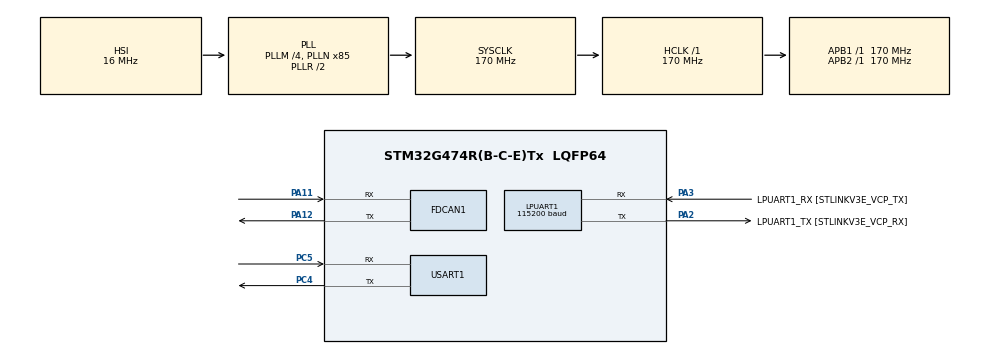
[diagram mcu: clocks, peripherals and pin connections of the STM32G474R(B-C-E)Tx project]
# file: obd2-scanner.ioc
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FDCAN1.CalculateBaudRateNominal=500000
FDCAN1.CalculateTimeBitNominal=2000
FDCAN1.CalculateTimeQuantumNominal=100.0
FDCAN1.NominalPrescaler=17
FDCAN1.NominalTimeSeg1=15
FDCAN1.NominalTimeSeg2=4
FDCAN1.StdFiltersNbr=1
FREERTOS.Tasks01=defaultTask,24,128,StartDefaultTask,Default,NULL,Dynamic,NULL,NULL
LPUART1.BaudRate=115200
Mcu.Family=STM32G4
Mcu.Name=STM32G474R(B-C-E)Tx
Mcu.Package=LQFP64
NVIC.FDCAN1_IT0_IRQn=true\:5\:0\:false\:false\:true\:true\:true\:true\:true
NVIC.PriorityGroup=NVIC_PRIORITYGROUP_4
NVIC.TIM6_DAC_IRQn=true\:15\:0\:false\:false\:true\:false\:false\:true\:true
NVIC.TimeBase=TIM6_DAC_IRQn
NVIC.TimeBaseIP=TIM6
PA11.Mode=FDCAN_Activate
PA11.Signal=FDCAN1_RX
PA12.Mode=FDCAN_Activate
PA12.Signal=FDCAN1_TX
PA13.GPIO_Label=T_SWDIO
PA13.Mode=Serial_Wire
PA13.Signal=SYS_JTMS-SWDIO
PA14.GPIO_Label=T_SWCLK
PA14.Mode=Serial_Wire
PA14.Signal=SYS_JTCK-SWCLK
PA2.GPIO_Label=LPUART1_TX [STLINKV3E_VCP_RX]
PA2.Mode=Asynchronous
PA2.Signal=LPUART1_TX
PA3.GPIO_Label=LPUART1_RX [STLINKV3E_VCP_TX]
PA3.Mode=Asynchronous
PA3.Signal=LPUART1_RX
PB3.GPIO_Label=T_SWO
PB3.Signal=SYS_JTDO-SWO
PC14-OSC32_IN.GPIO_Label=RCC_OSC32_IN
PC14-OSC32_IN.Mode=LSE-External-Oscillator
PC14-OSC32_IN.Signal=RCC_OSC32_IN
PC15-OSC32_OUT.GPIO_Label=RCC_OSC32_OUT
PC15-OSC32_OUT.Mode=LSE-External-Oscillator
PC15-OSC32_OUT.Signal=RCC_OSC32_OUT
PC4.Mode=Asynchronous
PC4.Signal=USART1_TX
PC5.Mode=Asynchronous
PC5.Signal=USART1_RX
PF0-OSC_IN.GPIO_Label=RCC_OSC_IN
PF0-OSC_IN.Mode=HSE-External-Clock-Source
PF0-OSC_IN.Signal=RCC_OSC_IN
PF1-OSC_OUT.GPIO_Label=RCC_OSC_OUT
PF1-OSC_OUT.Signal=RCC_OSC_OUT
ProjectManager.HeapSize=0x200
ProjectManager.StackSize=0x400
ProjectManager.TargetToolchain=CMake
RCC.ADC12Freq_Value=170000000
RCC.ADC345Freq_Value=170000000
RCC.AHBFreq_Value=170000000
RCC.APB1Freq_Value=170000000
RCC.APB1TimFreq_Value=170000000
RCC.APB2Freq_Value=170000000
RCC.APB2TimFreq_Value=170000000
RCC.CortexFreq_Value=170000000
RCC.EXTERNAL_CLOCK_VALUE=12288000
RCC.HCLKFreq_Value=170000000
RCC.HSE_VALUE=24000000
RCC.HSI48_VALUE=48000000
RCC.HSI_VALUE=16000000
RCC.PLLM=RCC_PLLM_DIV4
RCC.PLLN=85
RCC.RTCClockSelection=RCC_RTCCLKSOURCE_LSE
RCC.SYSCLKFreq_VALUE=170000000
RCC.SYSCLKSource=RCC_SYSCLKSOURCE_PLLCLK
RCC.USBFreq_Value=170000000
RCC.VCOOutputFreq_Value=340000000
USART1.VirtualMode-Asynchronous=VM_ASYNC
VP_FREERTOS_VS_CMSIS_V2.Mode=CMSIS_V2
VP_SYS_VS_DBSignals.Mode=DisableDeadBatterySignals
VP_SYS_VS_tim6.Mode=TIM6
board=NUCLEO-G474RE

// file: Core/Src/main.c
/* USER CODE BEGIN Header */
/**
  ******************************************************************************
  * @file           : main.c
  * @brief          : Main program body
  ******************************************************************************
  * @attention
  *
  * Copyright (c) 2026 STMicroelectronics.
  * All rights reserved.
  *
  * This software is licensed under terms that can be found in the LICENSE file
  * in the root directory of this software component.
  * If no LICENSE file comes with this software, it is provided AS-IS.
  *
  ******************************************************************************
  */
/* USER CODE END Header */
#include "main.h"
#include "cmsis_os.h"
#include "fdcan.h"
#include "usart.h"
#include "gpio.h"
#include <stdio.h>

void SystemClock_Config(void);
void MX_FREERTOS_Init(void);

/* USER CODE BEGIN 0 */
int _write(int file, char *ptr, int len)
{
  HAL_UART_Transmit(&hlpuart1, (uint8_t*) ptr, len, HAL_MAX_DELAY);
  return len;
}
/* USER CODE END 0 */

int main(void)
{

  /* MCU Configuration--------------------------------------------------------*/

  /* Reset of all peripherals, Initializes the Flash interface and the Systick. */
  HAL_Init();

  /* Configure the system clock */
  SystemClock_Config();

  /* Initialize all configured peripherals */
  MX_GPIO_Init();
  MX_FDCAN1_Init();
  MX_LPUART1_UART_Init();
  MX_USART1_UART_Init();
  /* USER CODE BEGIN 2 */

  // size_t free_heap = xPortGetFreeHeapSize(); // DEBUG
  // printf("free heap : %u", free_heap);

  /* USER CODE END 2 */

  /* Init scheduler */
  osKernelInitialize();  /* Call init function for freertos objects (in cmsis_os2.c) */
  MX_FREERTOS_Init();

  /* Start scheduler */
  osKernelStart();

  /* We should never get here as control is now taken by the scheduler */

  /* Infinite loop */
  while (1)
  {

  }
}

void SystemClock_Config(void)
{
  RCC_OscInitTypeDef RCC_OscInitStruct = {0};
  RCC_ClkInitTypeDef RCC_ClkInitStruct = {0};

  /** Configure the main internal regulator output voltage
  */
  HAL_PWREx_ControlVoltageScaling(PWR_REGULATOR_VOLTAGE_SCALE1_BOOST);

  /** Initializes the RCC Oscillators according to the specified parameters
  * in the RCC_OscInitTypeDef structure.
  */
  RCC_OscInitStruct.OscillatorType = RCC_OSCILLATORTYPE_HSI;
  RCC_OscInitStruct.HSIState = RCC_HSI_ON;
  RCC_OscInitStruct.HSICalibrationValue = RCC_HSICALIBRATION_DEFAULT;
  RCC_OscInitStruct.PLL.PLLState = RCC_PLL_ON;
  RCC_OscInitStruct.PLL.PLLSource = RCC_PLLSOURCE_HSI;
  RCC_OscInitStruct.PLL.PLLM = RCC_PLLM_DIV4;
  RCC_OscInitStruct.PLL.PLLN = 85;
  RCC_OscInitStruct.PLL.PLLP = RCC_PLLP_DIV2;
  RCC_OscInitStruct.PLL.PLLQ = RCC_PLLQ_DIV2;
  RCC_OscInitStruct.PLL.PLLR = RCC_PLLR_DIV2;
  if (HAL_RCC_OscConfig(&RCC_OscInitStruct) != HAL_OK)
  {
    Error_Handler();
  }

  /** Initializes the CPU, AHB and APB buses clocks
  */
  RCC_ClkInitStruct.ClockType = RCC_CLOCKTYPE_HCLK|RCC_CLOCKTYPE_SYSCLK
                              |RCC_CLOCKTYPE_PCLK1|RCC_CLOCKTYPE_PCLK2;
  RCC_ClkInitStruct.SYSCLKSource = RCC_SYSCLKSOURCE_PLLCLK;
  RCC_ClkInitStruct.AHBCLKDivider = RCC_SYSCLK_DIV1;
  RCC_ClkInitStruct.APB1CLKDivider = RCC_HCLK_DIV1;
  RCC_ClkInitStruct.APB2CLKDivider = RCC_HCLK_DIV1;

  if (HAL_RCC_ClockConfig(&RCC_ClkInitStruct, FLASH_LATENCY_4) != HAL_OK)
  {
    Error_Handler();
  }
}

void HAL_TIM_PeriodElapsedCallback(TIM_HandleTypeDef *htim)
{
  if (htim->Instance == TIM6)
  {
    HAL_IncTick();
  }
}

void Error_Handler(void)
{
  __disable_irq();
  while (1)
  {
  }
}

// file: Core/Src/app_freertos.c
/* USER CODE BEGIN Header */
/**
  ******************************************************************************
  * File Name          : app_freertos.c
  * Description        : Code for freertos applications
  ******************************************************************************
  * @attention
  *
  * Copyright (c) 2026 STMicroelectronics.
  * All rights reserved.
  *
  * This software is licensed under terms that can be found in the LICENSE file
  * in the root directory of this software component.
  * If no LICENSE file comes with this software, it is provided AS-IS.
  *
  ******************************************************************************
  */
/* USER CODE END Header */

#include "FreeRTOS.h"
#include "cmsis_os2.h"
#include "task.h"
#include "main.h"
#include "cmsis_os.h"

/* USER CODE BEGIN Includes */
#include "bridge.h"
#include "can.h"

/* USER CODE END Includes */

/* USER CODE BEGIN Variables */
const osMessageQueueAttr_t uartTxQueue_attributes = {
  .name = "uartTxQueue"
};
/* USER CODE END Variables */
/* Definitions for defaultTask */
osThreadId_t defaultTaskHandle;
const osThreadAttr_t defaultTask_attributes = {
  .name = "defaultTask",
  .priority = (osPriority_t) osPriorityNormal,
  .stack_size = 128 * 4
};

void StartDefaultTask(void *argument);

void MX_FREERTOS_Init(void); /* (MISRA C 2004 rule 8.1) */

void MX_FREERTOS_Init(void) {

  /* USER CODE BEGIN RTOS_SEMAPHORES */
  /* add semaphores, ... */
  uartTxSemHandle = osSemaphoreNew(1, 1, &uartTxSem_attributes);
  canRxSemHandler = osSemaphoreNew(1, 0, &canRxSem_attributes);
  /* USER CODE END RTOS_SEMAPHORES */

  /* USER CODE BEGIN RTOS_QUEUES */
  /* add queues, ... */
  uartTxQueueHandle = osMessageQueueNew (16, sizeof(TelemetryPacket), &uartTxQueue_attributes);
  /* USER CODE END RTOS_QUEUES */

  /* Create the thread(s) */
  /* creation of defaultTask */
  defaultTaskHandle = osThreadNew(StartDefaultTask, NULL, &defaultTask_attributes);

  /* USER CODE BEGIN RTOS_THREADS */
  /* add threads, ... */
  // sendDataToAppHandler = osThreadNew(sendDataToAppTask, NULL, &sendDataToAppAttr); // CAN -> UART TX Queue - DEBUG
  getCarTelemetryDataHandler = osThreadNew(getCarTelemetryData, NULL, &getCarTelemetryDataAttr);
  sendToDeviceUartTaskHandle = osThreadNew(sendToDeviceTask, NULL, &sendToDeviceUartAttr); // UART TX MESSAGE QUEUE -> UART TX
  /* USER CODE END RTOS_THREADS */

}

void StartDefaultTask(void *argument)
{
  /* USER CODE BEGIN StartDefaultTask */
  /* Infinite loop */
  for(;;)
  {
    osDelay(1000);
  }
  /* USER CODE END StartDefaultTask */
}
